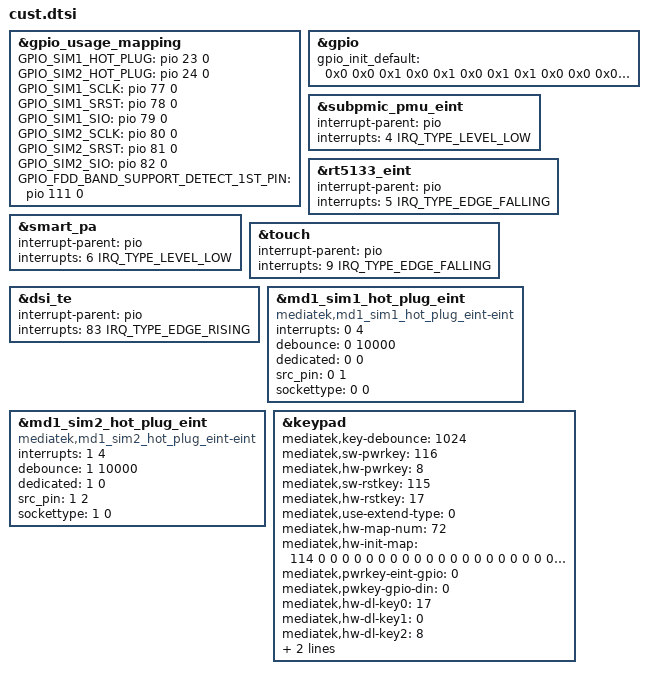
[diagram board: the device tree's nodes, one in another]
/*
 * Generated by MTK SP DrvGen Version: 3.5.160809 for MT6789.
 * 2023-05-09 02:06:17
 * Do Not Modify The File.
 * Copyright Mediatek Inc. (c) 2016.
*/

/*************************
 * ADC DTSI File
*************************/



/*************************
 * CLK_BUF DTSI File
*************************/



/*************************
 * I2C DTSI File
*************************/



/*************************
 * GPIO DTSI File
*************************/

&gpio_usage_mapping {
	GPIO_SIM1_HOT_PLUG = <&pio 23 0>;
	GPIO_SIM2_HOT_PLUG = <&pio 24 0>;
	GPIO_SIM1_SCLK = <&pio 77 0>;
	GPIO_SIM1_SRST = <&pio 78 0>;
	GPIO_SIM1_SIO = <&pio 79 0>;
	GPIO_SIM2_SCLK = <&pio 80 0>;
	GPIO_SIM2_SRST = <&pio 81 0>;
	GPIO_SIM2_SIO = <&pio 82 0>;
	GPIO_FDD_BAND_SUPPORT_DETECT_1ST_PIN = <&pio 111 0>;
};

&gpio{
	gpio_init_default = <0x0 0x0 0x1 0x0 0x1 0x0 0x1 0x1 0x0 0x0 0x0 0x1 0x0 0x1 0x2 0x0 0x0 0x0 0x1 0x0 0x1 0x3 0x0 0x1 0x0 0x1 0x0 0x1 0x4 0x0 0x0 0x0 0x1 0x1 0x1 0x5 0x0 0x0 0x0 0x1 0x1 0x1 0x6 0x0 0x0 0x0 0x1 0x1 0x1 0x7 0x0 0x0 0x0 0x1 0x1 0x1 0x8 0x0 0x0 0x0 0x1 0x0 0x1 0x9 0x0 0x0 0x0 0x1 0x1 0x1 0xa 0x0 0x0 0x0 0x1 0x0 0x1 0xb 0x0 0x0 0x0 0x1 0x1 0x1 0xc 0x0 0x0 0x0 0x1 0x0 0x1 0xd 0x6 0x0 0x0 0x1 0x0 0x1 0xe 0x6 0x0 0x0 0x1 0x0 0x0 0xf 0x0 0x1 0x0 0x1 0x0 0x0 0x10 0x0 0x1 0x0 0x1 0x0 0x0 0x11 0x0 0x0 0x0 0x1 0x0 0x0 0x12 0x0 0x1 0x0 0x1 0x0 0x0 0x13 0x0 0x1 0x0 0x1 0x0 0x0 0x14 0x0 0x1 0x0 0x1 0x0 0x0 0x15 0x0 0x1 0x0 0x1 0x0 0x0 0x16 0x0 0x1 0x0 0x1 0x0 0x0 0x17 0x1 0x0 0x0 0x1 0x1 0x0 0x18 0x1 0x0 0x0 0x1 0x1 0x0 0x19 0x2 0x0 0x0 0x1 0x0 0x1 0x1a 0x3 0x0 0x0 0x1 0x1 0x1 0x1b 0x1 0x1 0x0 0x1 0x0 0x1 0x1c 0x1 0x0 0x0 0x1 0x1 0x1 0x1d 0x1 0x0 0x0 0x0 0x0 0x1 0x1e 0x1 0x0 0x0 0x0 0x0 0x1 0x1f 0x1 0x0 0x0 0x0 0x0 0x1 0x20 0x1 0x0 0x0 0x0 0x0 0x1 0x21 0x1 0x0 0x0 0x1 0x0 0x1 0x22 0x6 0x0 0x0 0x1 0x0 0x0 0x23 0x6 0x0 0x0 0x1 0x0 0x0 0x24 0x6 0x0 0x0 0x0 0x0 0x0 0x25 0x6 0x0 0x0 0x1 0x0 0x0 0x26 0x2 0x0 0x0 0x0 0x0 0x1 0x27 0x2 0x0 0x0 0x0 0x0 0x1 0x28 0x2 0x0 0x0 0x0 0x0 0x1 0x29 0x2 0x0 0x0 0x1 0x0 0x1 0x2a 0x4 0x0 0x0 0x1 0x1 0x0 0x2b 0x4 0x0 0x0 0x0 0x0 0x0 0x2c 0x4 0x0 0x0 0x1 0x1 0x0 0x2d 0x4 0x0 0x0 0x0 0x0 0x0 0x2e 0x6 0x0 0x0 0x1 0x0 0x0 0x2f 0x6 0x0 0x0 0x1 0x0 0x0 0x30 0x6 0x0 0x0 0x0 0x0 0x0 0x31 0x6 0x0 0x0 0x1 0x0 0x0 0x32 0x2 0x0 0x0 0x0 0x0 0x1 0x33 0x2 0x0 0x0 0x0 0x0 0x1 0x34 0x2 0x0 0x0 0x0 0x0 0x1 0x35 0x2 0x0 0x0 0x1 0x0 0x1 0x42 0x1 0x0 0x0 0x1 0x1 0x0 0x43 0x0 0x0 0x0 0x1 0x0 0x1 0x44 0x0 0x0 0x0 0x1 0x0 0x1 0x45 0x0 0x0 0x0 0x1 0x1 0x1 0x4d 0x1 0x0 0x0 0x0 0x0 0x1 0x4e 0x1 0x0 0x0 0x0 0x0 0x1 0x4f 0x1 0x0 0x0 0x1 0x1 0x1 0x50 0x1 0x0 0x0 0x0 0x0 0x1 0x51 0x1 0x0 0x0 0x0 0x0 0x1 0x52 0x1 0x0 0x0 0x1 0x1 0x1 0x53 0x1 0x0 0x0 0x1 0x0 0x1 0x54 0x1 0x0 0x0 0x0 0x0 0x1 0x55 0x1 0x0 0x0 0x0 0x0 0x1 0x56 0x1 0x0 0x0 0x1 0x0 0x0 0x57 0x1 0x0 0x0 0x1 0x0 0x0 0x58 0x1 0x0 0x0 0x1 0x0 0x0 0x59 0x1 0x0 0x0 0x1 0x0 0x0 0x5a 0x1 0x0 0x0 0x1 0x0 0x0 0x5b 0x1 0x0 0x0 0x1 0x0 0x0 0x5c 0x1 0x0 0x0 0x1 0x0 0x0 0x5d 0x1 0x0 0x0 0x1 0x0 0x0 0x5e 0x1 0x0 0x0 0x1 0x0 0x0 0x5f 0x1 0x0 0x0 0x1 0x0 0x0 0x60 0x1 0x0 0x0 0x1 0x0 0x0 0x61 0x1 0x0 0x0 0x1 0x0 0x0 0x62 0x1 0x0 0x0 0x1 0x0 0x0 0x63 0x1 0x0 0x0 0x1 0x0 0x0 0x64 0x0 0x0 0x0 0x1 0x0 0x0 0x65 0x0 0x0 0x0 0x1 0x0 0x0 0x66 0x1 0x0 0x0 0x1 0x0 0x0 0x67 0x2 0x0 0x0 0x1 0x0 0x0 0x68 0x2 0x0 0x0 0x0 0x0 0x0 0x69 0x1 0x0 0x0 0x1 0x0 0x0 0x6a 0x1 0x0 0x0 0x1 0x0 0x0 0x6b 0x0 0x1 0x0 0x1 0x0 0x0 0x6c 0x1 0x0 0x0 0x1 0x0 0x0 0x6d 0x1 0x0 0x0 0x1 0x0 0x0 0x6e 0x1 0x0 0x0 0x1 0x0 0x0 0x6f 0x0 0x0 0x0 0x0 0x0 0x0 0x70 0x1 0x0 0x0 0x0 0x0 0x0 0x71 0x1 0x0 0x0 0x1 0x0 0x0 0x72 0x1 0x0 0x0 0x0 0x0 0x0 0x73 0x1 0x0 0x0 0x1 0x0 0x0 0x74 0x1 0x0 0x0 0x0 0x0 0x0 0x75 0x1 0x0 0x0 0x1 0x0 0x0 0x76 0x1 0x0 0x0 0x0 0x0 0x0 0x77 0x1 0x0 0x0 0x1 0x0 0x0 0x78 0x1 0x0 0x0 0x0 0x0 0x0 0x79 0x1 0x0 0x0 0x1 0x0 0x0 0x7a 0x1 0x0 0x0 0x0 0x0 0x0 0x7b 0x1 0x0 0x0 0x0 0x0 0x0 0x7c 0x1 0x0 0x0 0x1 0x0 0x0 0x7d 0x1 0x0 0x0 0x1 0x0 0x0 0x7e 0x1 0x0 0x0 0x1 0x0 0x0 0x7f 0x1 0x0 0x0 0x1 0x0 0x0 0x80 0x1 0x0 0x0 0x1 0x0 0x0 0x81 0x1 0x0 0x0 0x1 0x0 0x0 0x82 0x1 0x0 0x0 0x1 0x1 0x1 0x83 0x1 0x0 0x0 0x1 0x1 0x1 0x84 0x2 0x0 0x0 0x1 0x1 0x0 0x85 0x2 0x0 0x0 0x1 0x1 0x0 0x86 0x1 0x0 0x0 0x1 0x1 0x1 0x87 0x1 0x0 0x0 0x1 0x1 0x1 0x88 0x7 0x0 0x0 0x1 0x1 0x1 0x89 0x7 0x0 0x0 0x0 0x0 0x1 0x8a 0x1 0x0 0x0 0x1 0x1 0x1 0x8b 0x1 0x0 0x0 0x1 0x1 0x1 0x8c 0x1 0x0 0x0 0x1 0x1 0x1 0x8d 0x1 0x0 0x0 0x1 0x1 0x1 0x8e 0x1 0x0 0x0 0x1 0x1 0x1 0x8f 0x1 0x0 0x0 0x1 0x1 0x1 0x90 0x1 0x0 0x0 0x1 0x1 0x1 0x91 0x1 0x0 0x0 0x1 0x1 0x1 0x92 0x1 0x0 0x0 0x1 0x1 0x1 0x93 0x1 0x0 0x0 0x1 0x1 0x1 0x94 0x2 0x0 0x0 0x1 0x1 0x1 0x95 0x2 0x0 0x0 0x1 0x1 0x1 0x96 0x0 0x1 0x0 0x1 0x0 0x1 0x97 0x0 0x1 0x1 0x1 0x0 0x1 0x98 0x0 0x1 0x0 0x1 0x0 0x1 0x99 0x0 0x0 0x0 0x1 0x0 0x1 0x9a 0x0 0x1 0x0 0x1 0x0 0x1 0x9b 0x0 0x1 0x0 0x1 0x0 0x1 0x9c 0x0 0x1 0x0 0x1 0x0 0x1 0x9d 0x0 0x1 0x0 0x1 0x0 0x1 0x9e 0x0 0x1 0x0 0x1 0x0 0x0 0x9f 0x0 0x1 0x0 0x1 0x0 0x0 0xa0 0x1 0x0 0x0 0x0 0x0 0x1 0xa1 0x1 0x0 0x0 0x0 0x0 0x1 0xa2 0x1 0x0 0x0 0x0 0x0 0x1 0xa3 0x1 0x0 0x0 0x1 0x0 0x1 0xa4 0x1 0x0 0x0 0x0 0x0 0x1 0xa5 0x1 0x0 0x0 0x0 0x0 0x1 0xa6 0x1 0x0 0x0 0x0 0x0 0x1 0xa7 0x1 0x0 0x0 0x1 0x0 0x1 0xa8 0x1 0x0 0x0 0x0 0x0 0x0 0xa9 0x1 0x0 0x0 0x0 0x0 0x1 0xaa 0x1 0x0 0x0 0x0 0x0 0x1 0xab 0x1 0x0 0x0 0x0 0x0 0x1 0xac 0x1 0x0 0x0 0x0 0x0 0x1 0xad 0x1 0x0 0x0 0x1 0x0 0x1 0xae 0x1 0x0 0x0 0x1 0x0 0x1 0xaf 0x1 0x0 0x0 0x1 0x0 0x1 0xb0 0x1 0x0 0x0 0x1 0x0 0x1 0xb1 0x0 0x0 0x0 0x1 0x0 0x0 0xb2 0x0 0x0 0x0 0x1 0x0 0x0 0xb3 0x0 0x0 0x0 0x1 0x0 0x0 0xb4 0x0 0x0 0x0 0x1 0x0 0x0 0xb5 0x0 0x0 0x0 0x1 0x0 0x0 0xb6 0x0 0x0 0x0 0x1 0x0 0x0 0xb7 0x0 0x0 0x0 0x1 0x0 0x0 0xb8 0x0 0x0 0x0 0x1 0x0 0x0 0xb9 0x0 0x0 0x0 0x1 0x0 0x0 0xba 0x1 0x0 0x0 0x1 0x1 0x1 0xbb 0x1 0x0 0x0 0x1 0x1 0x1 0xbc 0x0 0x0 0x0 0x1 0x0 0x0 0xbd 0x0 0x0 0x0 0x1 0x0 0x0 0xbe 0x0 0x0 0x0 0x1 0x0 0x0 0xbf 0x0 0x0 0x0 0x1 0x0 0x0 0xc0 0x0 0x0 0x0 0x1 0x0 0x0 0xc1 0x0 0x0 0x0 0x1 0x0 0x0 0xc2 0x0 0x0 0x0 0x1 0x0 0x0 0xc3 0x0 0x0 0x0 0x1 0x0 0x0 0xc4 0x0 0x0 0x0 0x1 0x0 0x0 0xc5 0x0 0x0 0x0 0x1 0x0 0x0 0xc6 0x0 0x0 0x0 0x1 0x0 0x0 0xc7 0x0 0x0 0x0 0x1 0x0 0x0 0xc8 0x0 0x0 0x0 0x1 0x0 0x0 0xc9 0x0 0x0 0x0 0x1 0x0 0x0 0xca 0x0 0x0 0x0 0x1 0x0 0x0 0xcb 0x0 0x0 0x0 0x1 0x0 0x0 0xcc 0x0 0x0 0x0 0x1 0x0 0x0 0xcd 0x0 0x0 0x0 0x1 0x0 0x0 0xce 0x0 0x0 0x0 0x1 0x0 0x0 0xcf 0x0 0x0 0x0 0x1 0x0 0x0 0xd0 0x0 0x0 0x0 0x1 0x0 0x0 0xd1 0x0 0x0 0x0 0x1 0x0 0x0 0xd2 0x0 0x0 0x0 0x1 0x0 0x0 0xd3 0x0 0x0 0x0 0x1 0x0 0x0 0xd4 0x0 0x0 0x0 0x1 0x0 0x0 0xd5 0x0 0x0 0x0 0x1 0x0 0x0 0xd6 0x0 0x0 0x0 0x1 0x0 0x0 0xd7 0x0 0x0 0x0 0x1 0x0 0x0 0xd8 0x0 0x0 0x0 0x1 0x0 0x0 0xd9 0x0 0x0 0x0 0x1 0x0 0x0 0xda 0x0 0x0 0x0 0x1 0x0 0x0 0xdb 0x0 0x0 0x0 0x1 0x0 0x0 0xdc 0x0 0x0 0x0 0x1 0x0 0x0 0xdd 0x0 0x0 0x0 0x1 0x0 0x0>;
};


/*************************
 * EINT DTSI File
*************************/

#include <dt-bindings/interrupt-controller/irq.h>
#include <dt-bindings/interrupt-controller/arm-gic.h>

&subpmic_pmu_eint {
	interrupt-parent = <&pio>;
	interrupts = <4 IRQ_TYPE_LEVEL_LOW>;
	status = "okay";
};

&rt5133_eint {
	interrupt-parent = <&pio>;
	interrupts = <5 IRQ_TYPE_EDGE_FALLING>;
	status = "okay";
};

&smart_pa {
	interrupt-parent = <&pio>;
	interrupts = <6 IRQ_TYPE_LEVEL_LOW>;
	status = "okay";
};

&touch {
	interrupt-parent = <&pio>;
	interrupts = <9 IRQ_TYPE_EDGE_FALLING>;
	status = "okay";
};

&dsi_te {
	interrupt-parent = <&pio>;
	interrupts = <83 IRQ_TYPE_EDGE_RISING>;
	status = "okay";
};



/*************************
 * MD1_EINT DTSI File
*************************/

&md1_sim1_hot_plug_eint {
	compatible = "mediatek,md1_sim1_hot_plug_eint-eint";
	interrupts = <0 4>;
	debounce = <0 10000>;
	dedicated = <0 0>;
	src_pin = <0 1>;
	sockettype = <0 0>;
	status = "okay";
};

&md1_sim2_hot_plug_eint {
	compatible = "mediatek,md1_sim2_hot_plug_eint-eint";
	interrupts = <1 4>;
	debounce = <1 10000>;
	dedicated = <1 0>;
	src_pin = <1 2>;
	sockettype = <1 0>;
	status = "okay";
};



/*************************
 * PMIC DTSI File
*************************/



/*************************
 * POWER DTSI File
*************************/



/*************************
 * KPD DTSI File
*************************/

&keypad {
	mediatek,key-debounce = <1024>;
	mediatek,sw-pwrkey = <116>;
	mediatek,hw-pwrkey = <8>;
	mediatek,sw-rstkey  = <115>;
	mediatek,hw-rstkey = <17>;
	mediatek,use-extend-type = <0>;
	/*HW Keycode [0~71] -> Linux Keycode*/
	mediatek,hw-map-num = <72>;
	mediatek,hw-init-map = <114 0 0 0 0 0 0 0 0 0 0 0 0 0 0 0 0 0 0 0 0 0 0 0 0 0 0 0 0 0 0 0 0 0 0 0 0 0 0 0 0 0 0 0 0 0 0 0 0 0 0 0 0 0 0 0 0 0 0 0 0 0 0 0 0 0 0 0 0 0 0 0 >;
	mediatek,pwrkey-eint-gpio = <0>;
	mediatek,pwkey-gpio-din  = <0>;
	mediatek,hw-dl-key0 = <17>;
	mediatek,hw-dl-key1 = <0>;
	mediatek,hw-dl-key2 = <8>;
	mediatek,hw-recovery-key = <17>;
	mediatek,hw-factory-key = <0>;
	status = "okay";
};


